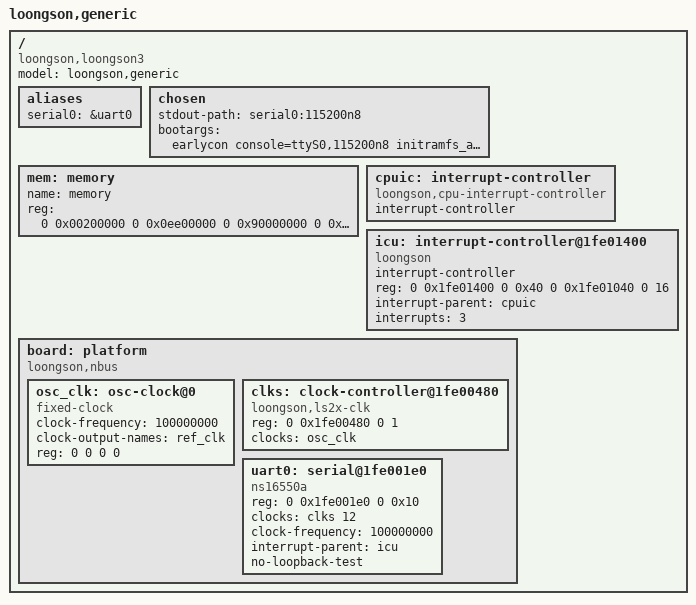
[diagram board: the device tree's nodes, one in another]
/dts-v1/;
/*
This is a customized dts file for 3A5000+7A2000 board.
wheatfox 2024
*/
#include "loongson3.dtsi"
/ {
	model = "loongson,generic";
	compatible = "loongson,loongson3";
	#address-cells = <2>;
	#size-cells = <2>;
	
	aliases {
		serial0 = &uart0;
		// serial1 = &uart1;
	};
	
	chosen {
		stdout-path = "serial0:115200n8";
		bootargs = "earlycon console=ttyS0,115200n8 initramfs_async=false rootwait";
		// linux,initrd-start = <0 0x90000000>;
		// linux,initrd-end = <0 0x93c00000>; // size = 60M ext4
	};
	
	mem: memory {
		name = "memory";
		device_type = "memory";
		// reg =  <0 0x00200000 0 0x0ee00000
		// 0 0x90000000 0 0x10000000>;
		reg =  <0 0x00200000 0 0x0ee00000
		0 0x90000000 0 0x10000000>;
	};
	
	cpuic: interrupt-controller {
		compatible = "loongson,cpu-interrupt-controller";
		interrupt-controller;
		#interrupt-cells = <1>;
	};
	
	icu: interrupt-controller@1fe01400 {
		compatible = "loongson";
		interrupt-controller;
		#interrupt-cells = <1>;
		reg = <0 0x1fe01400 0 0x40
		0 0x1fe01040 0 16>;
		interrupt-parent = <&cpuic>;
		interrupt-names = "cascade";
		interrupts = <3>; /* HW IP1 */
	};
	
	board: platform {
		compatible = "loongson,nbus", "simple-bus";
		#address-cells = <2>;
		#size-cells = <2>;
		// enable-lpc-irq;
		// ranges = <0x000 0x00000000 0x000 0x00000000 0x20000000
		// 	  0x000 0x40000000 0x000 0x40000000 0x40000000
		// 	  0xe00 0x00000000 0xe00 0x00000000 0x80000000>;
		ranges = <0 0x10000000 0 0x10000000 0 0x10000000
		0 0x2000000  0 0x2000000  0 0x2000000
		0 0x20000000 0 0x20000000 0 0x10000000
		0 0x40000000 0 0x40000000 0 0x40000000
		0xfe 0x00000000 0xfe 0x00000000 0 0x40000000>;
		
		osc_clk: osc-clock@0 {
			#clock-cells = <0>;
			compatible = "fixed-clock";
			clock-frequency = <100000000>;
			clock-output-names = "ref_clk";
			reg = <0 0 0 0>;
		};
		
		clks: clock-controller@1fe00480 {
			compatible = "loongson,ls2x-clk";
			reg = <0 0x1fe00480 0 1>;
			clocks = <&osc_clk>;
			clock-names = "ref_clk";
			#clock-cells = <1>;
		};
		
		uart0: serial@1fe001e0 {
			device_type = "serial";
			compatible = "ns16550a";
			reg = <0 0x1fe001e0 0 0x10>;
			clocks = <&clks 12>;
			clock-frequency = <100000000>;
			// interrupts = <10>;
			interrupt-parent = <&icu>;
			no-loopback-test;
			status = "okay";
		};

		// uart1: serial@1fe001e8 {
		// 	device_type = "serial";
		// 	compatible = "ns16550a";
		// 	reg = <0 0x1fe001e8 0 0x10>;
		// 	clocks = <&clks 12>;
		// 	clock-frequency = <100000000>;
		// 	// interrupts = <11>;
		// 	// interrupt-parent = <&icu>;
		// 	no-loopback-test;
		// 	status = "disabled";
		// };
	};
};
